# STM32H747_CM7 register map
File version: 2.3
CPU: CM7 r0p1, little endian, MPU, FPU, 4 interrupt priority bits
Registers are 32-bit, read-write, reset 0x0 unless marked. A register's access mark holds for its fields unless they carry their own. Offsets are from the block's base; [hi:lo] are bit positions; {n}, {i} and the like mark numbered series; 'fields as' and 'values as' point back to an identical list.

## AXI — AXI interconnect registers
Base 0x51000000
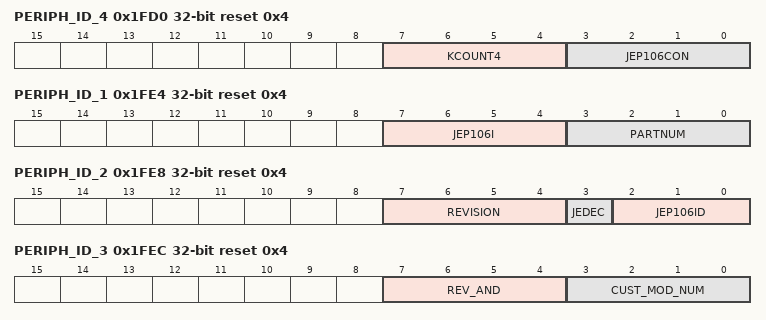
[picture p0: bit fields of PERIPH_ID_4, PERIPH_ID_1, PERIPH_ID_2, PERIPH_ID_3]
0x1FD0 PERIPH_ID_4 ro reset 0x4 — AXI interconnect - peripheral ID4 register
  [7:4] KCOUNT4 — Register file size
  [3:0] JEP106CON — JEP106 continuation code
0x1FE0 PERIPH_ID_0 ro reset 0x4 — AXI interconnect - peripheral ID0 register
  [7:0] PARTNUM — Peripheral part number bits 0 to 7
0x1FE4 PERIPH_ID_1 ro reset 0x4 — AXI interconnect - peripheral ID1 register
  [7:4] JEP106I — JEP106 identity bits 0 to 3
  [3:0] PARTNUM — Peripheral part number bits 8 to 11
0x1FE8 PERIPH_ID_2 ro reset 0x4 — AXI interconnect - peripheral ID2 register
  [7:4] REVISION — Peripheral revision number
  [3] JEDEC — JEP106 code flag
  [2:0] JEP106ID — JEP106 Identity bits 4 to 6
0x1FEC PERIPH_ID_3 ro reset 0x4 — AXI interconnect - peripheral ID3 register
  [7:4] REV_AND — Customer version
  [3:0] CUST_MOD_NUM — Customer modification
0x1FF0 COMP_ID_0 ro reset 0x4 — AXI interconnect - component ID0 register
  [7:0] PREAMBLE — Preamble bits 0 to 7
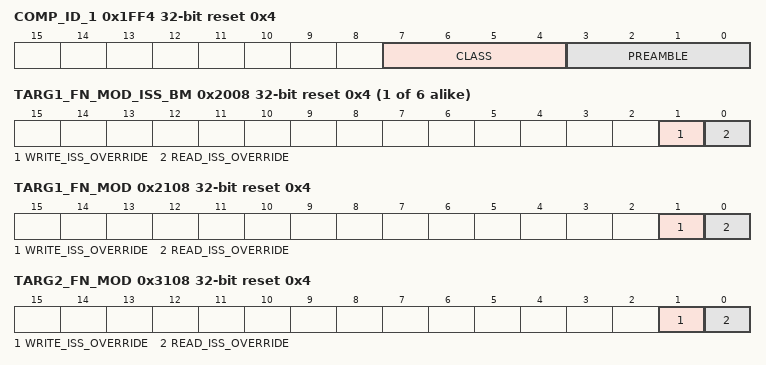
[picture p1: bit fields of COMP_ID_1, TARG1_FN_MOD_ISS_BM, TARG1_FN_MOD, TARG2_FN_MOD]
0x1FF4 COMP_ID_1 ro reset 0x4 — AXI interconnect - component ID1 register
  [7:4] CLASS — Component class
  [3:0] PREAMBLE — Preamble bits 8 to 11
0x1FF8 COMP_ID_2 ro reset 0x4 — AXI interconnect - component ID2 register
  [7:0] PREAMBLE — Preamble bits 12 to 19
0x1FFC COMP_ID_3 ro reset 0x4 — AXI interconnect - component ID3 register
  [7:0] PREAMBLE — Preamble bits 20 to 27
{0x1008+0x1000*i} TARG{i}_FN_MOD_ISS_BM reset 0x4 (i=1..6) — AXI interconnect - TARG x bus matrix issuing functionality register
  [1] WRITE_ISS_OVERRIDE — Switch matrix write issuing override for target
  [0] READ_ISS_OVERRIDE
0x2024 TARG1_FN_MOD2 reset 0x4 — AXI interconnect - TARG x bus matrix functionality 2 register
  [0] BYPASS_MERGE — Disable packing of beats to match the output data width
0x202C TARG1_FN_MOD_LB reset 0x4 — AXI interconnect - TARG x long burst functionality modification
  [0] FN_MOD_LB — Controls burst breaking of long bursts
0x2108 TARG1_FN_MOD reset 0x4 — AXI interconnect - TARG x long burst functionality modification
  [1] WRITE_ISS_OVERRIDE — Override AMIB write issuing capability
  [0] READ_ISS_OVERRIDE — Override AMIB read issuing capability
0x3024 TARG2_FN_MOD2 reset 0x4 — AXI interconnect - TARG x bus matrix functionality 2 register
  fields as TARG1_FN_MOD2
0x302C TARG2_FN_MOD_LB reset 0x4 — AXI interconnect - TARG x long burst functionality modification
  [0] FN_MOD_LB — Controls burst breaking of long bursts
0x3108 TARG2_FN_MOD reset 0x4 — AXI interconnect - TARG x long burst functionality modification
  fields as TARG1_FN_MOD
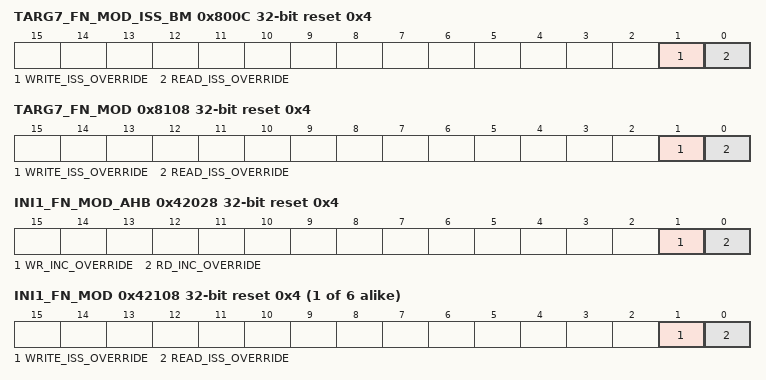
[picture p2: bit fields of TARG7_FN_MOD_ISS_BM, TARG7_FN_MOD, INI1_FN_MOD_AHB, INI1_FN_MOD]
0x800C TARG7_FN_MOD_ISS_BM reset 0x4 — AXI interconnect - TARG x bus matrix issuing functionality register
  fields as TARG1_FN_MOD_ISS_BM
0x8024 TARG7_FN_MOD2 reset 0x4 — AXI interconnect - TARG x bus matrix functionality 2 register
  fields as TARG1_FN_MOD2
0x8108 TARG7_FN_MOD reset 0x4 — AXI interconnect - TARG x long burst functionality modification
  fields as TARG1_FN_MOD
0x42024 INI1_FN_MOD2 reset 0x4 — AXI interconnect - INI x functionality modification 2 register
  [0] BYPASS_MERGE — Disables alteration of transactions by the up-sizer unless required by the protocol
0x42028 INI1_FN_MOD_AHB reset 0x4 — AXI interconnect - INI x AHB functionality modification register
  [1] WR_INC_OVERRIDE — Converts all AHB-Lite read transactions to a series of single beat AXI
  [0] RD_INC_OVERRIDE — Converts all AHB-Lite write transactions to a series of single beat AXI
{0x41100+0x1000*i} INI{i}_READ_QOS reset 0x4 (i=1..6) — AXI interconnect - INI x read QoS register
  [3:0] AR_QOS — Read channel QoS setting
{0x41104+0x1000*i} INI{i}_WRITE_QOS reset 0x4 (i=1..6) — AXI interconnect - INI x write QoS register
  [3:0] AW_QOS — Write channel QoS setting
{0x41108+0x1000*i} INI{i}_FN_MOD reset 0x4 (i=1..6) — AXI interconnect - INI x issuing functionality modification register
  [1] WRITE_ISS_OVERRIDE — Override ASIB write issuing capability
    0=Normal ASIB write issuing capability; 1=Force1 (Force ASIB write issuing capability to 1)
  [0] READ_ISS_OVERRIDE — Override ASIB read issuing capability
    0=Normal ASIB read issuing capability; 1=Force1 (Force ASIB read issuing capability to 1)
0x44024 INI3_FN_MOD2 reset 0x4 — AXI interconnect - INI x functionality modification 2 register
  fields as INI1_FN_MOD2
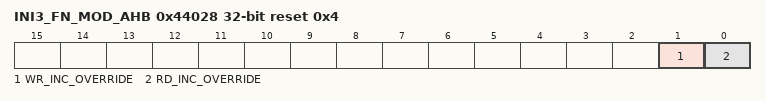
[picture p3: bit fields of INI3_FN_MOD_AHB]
0x44028 INI3_FN_MOD_AHB reset 0x4 — AXI interconnect - INI x AHB functionality modification register
  fields as INI1_FN_MOD_AHB
